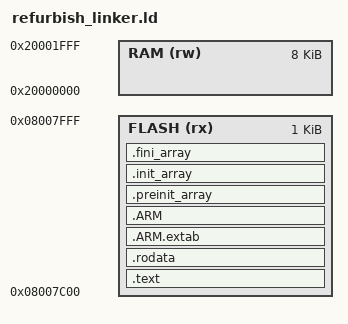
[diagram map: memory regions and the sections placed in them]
/*
*****************************************************************************
**
**  File        : refurbish_linker.ld
**
**  Abstract    : Link the refurbishing script to the proper
**                flash page, and set memory addresses
**
**
**  Target      : Schonherz Matrix MUEB (STM32F030C8T6)
**
**  Environment : GNU build environment
**
**
*****************************************************************************
*/

ENTRY(ref)

MEMORY{
    RAM   (rw)   : ORIGIN = 0x20000000, LENGTH = 8K
    FLASH (rx)   : ORIGIN = 0x8007C00, LENGTH = 1K
}

SECTIONS
{
  /* The program code and other data goes into FLASH */
  .text :
  {
    . = ALIGN(4);   
    
    *(.text.prologue);
    *(.text)           /* .text sections (code) */
    *(.text*)          /* .text* sections (code) */
    *(.glue_7)         /* glue arm to thumb code */
    *(.glue_7t)        /* glue thumb to arm code */
    *(.eh_frame)

    KEEP (*(.init))
    KEEP (*(.fini))

    . = ALIGN(4);
  } >FLASH

  /* Constant data goes into FLASH */
  .rodata :
  {
    . = ALIGN(4);
    *(.rodata)         /* .rodata sections (constants, strings, etc.) */
    *(.rodata*)        /* .rodata* sections (constants, strings, etc.) */
    . = ALIGN(4);
  } >FLASH

  .ARM.extab   : { *(.ARM.extab* .gnu.linkonce.armextab.*) } >FLASH
  .ARM : {
    *(.ARM.exidx*)
  } >FLASH

  .preinit_array     :
  {
    PROVIDE_HIDDEN (__preinit_array_start = .);
    KEEP (*(.preinit_array*))
    PROVIDE_HIDDEN (__preinit_array_end = .);
  } >FLASH
  .init_array :
  {
    PROVIDE_HIDDEN (__init_array_start = .);
    KEEP (*(SORT(.init_array.*)))
    KEEP (*(.init_array*))
    PROVIDE_HIDDEN (__init_array_end = .);
  } >FLASH
  .fini_array :
  {
    PROVIDE_HIDDEN (__fini_array_start = .);
    KEEP (*(SORT(.fini_array.*)))
    KEEP (*(.fini_array*))
    PROVIDE_HIDDEN (__fini_array_end = .);
  } >FLASH

  /* Remove information from the standard libraries */
  

  /DISCARD/ :
  {
    libc.a ( * )
    libm.a ( * )
    libgcc.a ( * )
  }

  .ARM.attributes 0 : { *(.ARM.attributes) }
}


